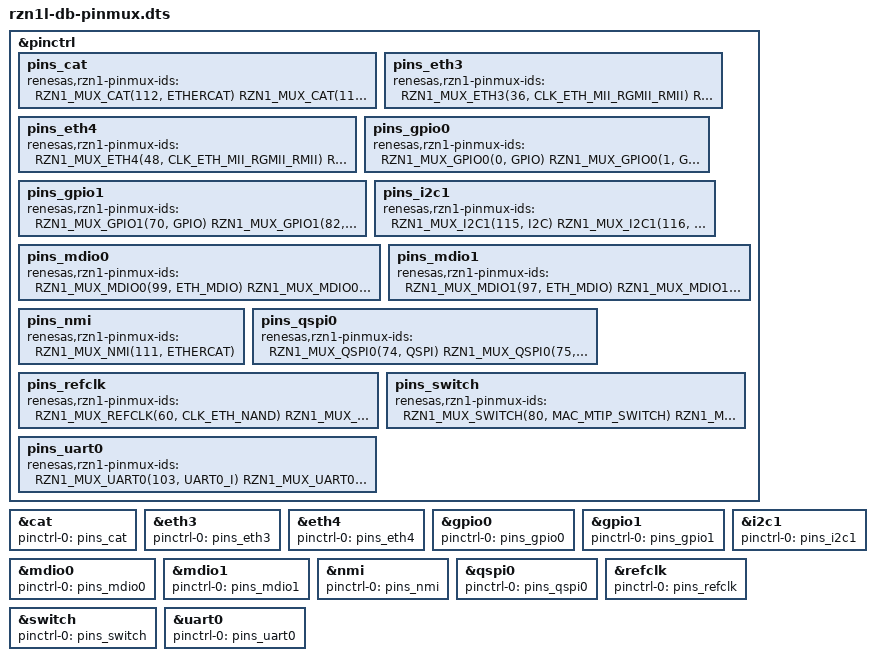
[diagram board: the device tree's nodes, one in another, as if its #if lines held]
/*
 * This file was autogenerated
 * DO NOT EDIT
 * (C) 2015-2016 Renesas Electronics Europe, LTD
 * All rights reserved.
 *
 * Redistribution and use in source and binary forms, with or without
 * modification, are permitted provided that the following conditions are met:
 *
 * 1. Redistributions of source code must retain the above copyright notice,
 * this list of conditions and the following disclaimer.
 *
 * 2. Redistributions in binary form must reproduce the above copyright notice,
 * this list of conditions and the following disclaimer in the documentation
 * and/or other materials provided with the distribution.
 *
 * THIS SOFTWARE IS PROVIDED BY THE COPYRIGHT HOLDERS AND CONTRIBUTORS "AS IS"
 * AND ANY EXPRESS OR IMPLIED WARRANTIES, INCLUDING, BUT NOT LIMITED TO, THE
 * IMPLIED WARRANTIES OF MERCHANTABILITY AND FITNESS FOR A PARTICULAR PURPOSE
 * ARE DISCLAIMED. IN NO EVENT SHALL THE COPYRIGHT HOLDER OR CONTRIBUTORS BE
 * LIABLE FOR ANY DIRECT, INDIRECT, INCIDENTAL, SPECIAL, EXEMPLARY, OR
 * CONSEQUENTIAL DAMAGES (INCLUDING, BUT NOT LIMITED TO, PROCUREMENT OF
 * SUBSTITUTE GOODS OR SERVICES; LOSS OF USE, DATA, OR PROFITS; OR BUSINESS
 * INTERRUPTION) HOWEVER CAUSED AND ON ANY THEORY OF LIABILITY, WHETHER IN
 * CONTRACT, STRICT LIABILITY, OR TORT (INCLUDING NEGLIGENCE OR OTHERWISE)
 * ARISING IN ANY WAY OUT OF THE USE OF THIS SOFTWARE, EVEN IF ADVISED OF THE
 * POSSIBILITY OF SUCH DAMAGE.
 */

#include "rzn1.dtsi"

/*
 * AUTOGENERATED DO NOT EDIT
 *
 * Renesas RZ/N1L-DB board
 * This file only sets the pin function by default.
 *
 * You can override the default mux pullup/down and drive by
 * defining the following macros in the board file before
 * including this.
 */

#ifndef RZN1_MUX_DEFAULT
#define RZN1_MUX_DEFAULT RZN1_MUX
#endif

#ifndef RZN1_MUX_CAT
#define RZN1_MUX_CAT RZN1_MUX_DEFAULT
#endif
#ifndef RZN1_MUX_ETH3
#define RZN1_MUX_ETH3 RZN1_MUX_PNONE_6MA
#endif
#ifndef RZN1_MUX_ETH4
#define RZN1_MUX_ETH4 RZN1_MUX_PNONE_6MA
#endif
#ifndef RZN1_MUX_GPIO
#define RZN1_MUX_GPIO RZN1_MUX_DEFAULT
#endif
#ifndef RZN1_MUX_GPIO0
#define RZN1_MUX_GPIO0 RZN1_MUX_GPIO
#endif
#ifndef RZN1_MUX_GPIO1
#define RZN1_MUX_GPIO1 RZN1_MUX_GPIO
#endif
#ifndef RZN1_MUX_I2C1
#define RZN1_MUX_I2C1 RZN1_MUX_12MA
#endif
#ifndef RZN1_MUX_MDIO
#define RZN1_MUX_MDIO RZN1_MUX_DEFAULT
#endif
#ifndef RZN1_MUX_MDIO0
#define RZN1_MUX_MDIO0 RZN1_MUX_MDIO
#endif
#ifndef RZN1_MUX_MDIO1
#define RZN1_MUX_MDIO1 RZN1_MUX_MDIO
#endif
#ifndef RZN1_MUX_NMI
#define RZN1_MUX_NMI RZN1_MUX_DEFAULT
#endif
#ifndef RZN1_MUX_QSPI0
#define RZN1_MUX_QSPI0 RZN1_MUX_PNONE
#endif
#ifndef RZN1_MUX_REFCLK
#define RZN1_MUX_REFCLK RZN1_MUX_PNONE
#endif
#ifndef RZN1_MUX_SWITCH
#define RZN1_MUX_SWITCH RZN1_MUX_DEFAULT
#endif
#ifndef RZN1_MUX_UART
#define RZN1_MUX_UART RZN1_MUX_DEFAULT
#endif
#ifndef RZN1_MUX_UART0
#define RZN1_MUX_UART0 RZN1_MUX_UART
#endif

&pinctrl {
	pins_cat: pins_cat {
		renesas,rzn1-pinmux-ids = <
			RZN1_MUX_CAT(112, ETHERCAT)	/* CAT_I2CDATA */
			RZN1_MUX_CAT(113, ETHERCAT)	/* CAT_I2CCLK */
		>;
	};
	pins_eth3: pins_eth3 {
		renesas,rzn1-pinmux-ids = <
			RZN1_MUX_ETH3(36, CLK_ETH_MII_RGMII_RMII)	/* ETH3_TXCLK */
			RZN1_MUX_ETH3(37, CLK_ETH_MII_RGMII_RMII)	/* ETH3_TXD[0] */
			RZN1_MUX_ETH3(38, CLK_ETH_MII_RGMII_RMII)	/* ETH3_TXD[1] */
			RZN1_MUX_ETH3(39, CLK_ETH_MII_RGMII_RMII)	/* ETH3_TXD[2] */
			RZN1_MUX_ETH3(40, CLK_ETH_MII_RGMII_RMII)	/* ETH3_TXD[3] */
			RZN1_MUX_ETH3(41, CLK_ETH_MII_RGMII_RMII)	/* ETH3_TXEN */
			RZN1_MUX_ETH3(42, CLK_ETH_MII_RGMII_RMII)	/* ETH3_RXCLK */
			RZN1_MUX_ETH3(43, CLK_ETH_MII_RGMII_RMII)	/* ETH3_RXD[0] */
			RZN1_MUX_ETH3(44, CLK_ETH_MII_RGMII_RMII)	/* ETH3_RXD[1] */
			RZN1_MUX_ETH3(45, CLK_ETH_MII_RGMII_RMII)	/* ETH3_RXD[2] */
			RZN1_MUX_ETH3(46, CLK_ETH_MII_RGMII_RMII)	/* ETH3_RXD[3] */
			RZN1_MUX_ETH3(47, CLK_ETH_MII_RGMII_RMII)	/* ETH3_RXDV */
			RZN1_MUX_ETH3(67, CLK_ETH_MII_RGMII_RMII)	/* ETH3_RXER */
			RZN1_MUX_ETH3(68, CLK_ETH_MII_RGMII_RMII)	/* ETH3_CRS */
			RZN1_MUX_ETH3(69, CLK_ETH_MII_RGMII_RMII)	/* ETH3_COL */
		>;
	};
	pins_eth4: pins_eth4 {
		renesas,rzn1-pinmux-ids = <
			RZN1_MUX_ETH4(48, CLK_ETH_MII_RGMII_RMII)	/* ETH4_TXCLK */
			RZN1_MUX_ETH4(49, CLK_ETH_MII_RGMII_RMII)	/* ETH4_TXD[0] */
			RZN1_MUX_ETH4(50, CLK_ETH_MII_RGMII_RMII)	/* ETH4_TXD[1] */
			RZN1_MUX_ETH4(51, CLK_ETH_MII_RGMII_RMII)	/* ETH4_TXD[2] */
			RZN1_MUX_ETH4(52, CLK_ETH_MII_RGMII_RMII)	/* ETH4_TXD[3] */
			RZN1_MUX_ETH4(53, CLK_ETH_MII_RGMII_RMII)	/* ETH4_TXEN */
			RZN1_MUX_ETH4(54, CLK_ETH_MII_RGMII_RMII)	/* ETH4_RXCLK */
			RZN1_MUX_ETH4(55, CLK_ETH_MII_RGMII_RMII)	/* ETH4_RXD[0] */
			RZN1_MUX_ETH4(56, CLK_ETH_MII_RGMII_RMII)	/* ETH4_RXD[1] */
			RZN1_MUX_ETH4(57, CLK_ETH_MII_RGMII_RMII)	/* ETH4_RXD[2] */
			RZN1_MUX_ETH4(58, CLK_ETH_MII_RGMII_RMII)	/* ETH4_RXD[3] */
			RZN1_MUX_ETH4(59, CLK_ETH_MII_RGMII_RMII)	/* ETH4_RXDV */
			RZN1_MUX_ETH4(71, CLK_ETH_MII_RGMII_RMII)	/* ETH4_RXER */
			RZN1_MUX_ETH4(72, CLK_ETH_MII_RGMII_RMII)	/* ETH4_CRS */
			RZN1_MUX_ETH4(73, CLK_ETH_MII_RGMII_RMII)	/* ETH4_COL */
		>;
	};
	pins_gpio0: pins_gpio0 {
		renesas,rzn1-pinmux-ids = <
			RZN1_MUX_GPIO0(0, GPIO)		/* GPIO0A[0] */
			RZN1_MUX_GPIO0(1, GPIO)		/* GPIO0B[0] */
			RZN1_MUX_GPIO0(2, GPIO)		/* GPIO0B[1] */
			RZN1_MUX_GPIO0(3, GPIO)		/* GPIO0A[1] */
			RZN1_MUX_GPIO0(4, GPIO)		/* GPIO0A[2] */
			RZN1_MUX_GPIO0(5, GPIO)		/* GPIO0B[2] */
			RZN1_MUX_GPIO0(6, GPIO)		/* GPIO0B[3] */
			RZN1_MUX_GPIO0(7, GPIO)		/* GPIO0B[4] */
			RZN1_MUX_GPIO0(8, GPIO)		/* GPIO0B[5] */
			RZN1_MUX_GPIO0(9, GPIO)		/* GPIO0A[3] */
			RZN1_MUX_GPIO0(10, GPIO)	/* GPIO0A[4] */
			RZN1_MUX_GPIO0(11, GPIO)	/* GPIO0B[6] */
			RZN1_MUX_GPIO0(62, GPIO)	/* GPIO0A[25] */
			RZN1_MUX_GPIO0(63, GPIO)	/* GPIO0A[26] */
			RZN1_MUX_GPIO0(64, GPIO)	/* GPIO0A[27] */
			RZN1_MUX_GPIO0(65, GPIO)	/* GPIO0A[28] */
			RZN1_MUX_GPIO0(66, GPIO)	/* Eth 0 reset (GPIO0A[29]) */
		>;
	};
	pins_gpio1: pins_gpio1 {
		renesas,rzn1-pinmux-ids = <
			RZN1_MUX_GPIO1(70, GPIO)	/* Eth 0 IRQ (GPIO1A[1]) */
			RZN1_MUX_GPIO1(82, GPIO)	/* GPIO1B[13] */
			RZN1_MUX_GPIO1(83, GPIO)	/* GPIO1B[14] */
			RZN1_MUX_GPIO1(84, GPIO)	/* GPIO1B[15] */
			RZN1_MUX_GPIO1(85, GPIO)	/* GPIO1B[16] */
			RZN1_MUX_GPIO1(86, GPIO)	/* GPIO1B[17] */
			RZN1_MUX_GPIO1(87, GPIO)	/* GPIO1B[18] */
			RZN1_MUX_GPIO1(88, GPIO)	/* GPIO1B[19] */
			RZN1_MUX_GPIO1(89, GPIO)	/* GPIO1B[20] */
			RZN1_MUX_GPIO1(90, GPIO)	/* GPIO1B[21] */
			RZN1_MUX_GPIO1(91, GPIO)	/* GPIO1B[22] */
			RZN1_MUX_GPIO1(92, GPIO)	/* GPIO1B[23] */
			RZN1_MUX_GPIO1(93, GPIO)	/* GPIO1B[24] */
			RZN1_MUX_GPIO1(94, GPIO)	/* Eth 3 and 4 reset (GPIO1B[25]) */
			RZN1_MUX_GPIO1(95, GPIO)	/* Eth 3 IRQ (GPIO1A[5]) */
			RZN1_MUX_GPIO1(96, GPIO)	/* Eth 4 IRQ (GPIO1A[6]) */
			RZN1_MUX_GPIO1(105, GPIO)	/* GPIO1A[15] */
			RZN1_MUX_GPIO1(106, GPIO)	/* GPIO1A[16] */
			RZN1_MUX_GPIO1(107, GPIO)	/* GPIO1A[17] */
			RZN1_MUX_GPIO1(108, GPIO)	/* GPIO1A[18] */
			RZN1_MUX_GPIO1(114, GPIO)	/* GPIO1A[24] */
			RZN1_MUX_GPIO1(117, GPIO)	/* GPIO1A[27] */
			RZN1_MUX_GPIO1(118, GPIO)	/* GPIO1A[28] */
		>;
	};
	pins_i2c1: pins_i2c1 {
		renesas,rzn1-pinmux-ids = <
			RZN1_MUX_I2C1(115, I2C)		/* I2C1_SCL */
			RZN1_MUX_I2C1(116, I2C)		/* I2C1_SDA */
		>;
	};
	pins_mdio0: pins_mdio0 {
		renesas,rzn1-pinmux-ids = <
			RZN1_MUX_MDIO0(99, ETH_MDIO)	/* MDIO0_MDC */
			RZN1_MUX_MDIO0(100, ETH_MDIO)	/* MDIO0_MDIO */
			RZN1_MUX_MDIO0(170, MDIO_MUX_MAC0)	/* MDIO0_MUX_MAC0 */
		>;
	};
	pins_mdio1: pins_mdio1 {
		renesas,rzn1-pinmux-ids = <
			RZN1_MUX_MDIO1(97, ETH_MDIO)	/* MDIO1_MDC */
			RZN1_MUX_MDIO1(98, ETH_MDIO)	/* MDIO1_MDIO */
			RZN1_MUX_MDIO1(171, MDIO_MUX_SWITCH)	/* MDIO1_MUX_SWITCH */
		>;
	};
	pins_nmi: pins_nmi {
		renesas,rzn1-pinmux-ids = <
			RZN1_MUX_NMI(111, ETHERCAT)	/* NMI_CORTEXM[3] */
		>;
	};
	pins_qspi0: pins_qspi0 {
		renesas,rzn1-pinmux-ids = <
			RZN1_MUX_QSPI0(74, QSPI)	/* QSPI0_CS_N[0] */
			RZN1_MUX_QSPI0(75, QSPI)	/* QSPI0_IO[3] */
			RZN1_MUX_QSPI0(76, QSPI)	/* QSPI0_IO[2] */
			RZN1_MUX_QSPI0(77, QSPI)	/* QSPI0_IO[1] */
			RZN1_MUX_QSPI0(78, QSPI)	/* QSPI0_IO[0] */
			RZN1_MUX_QSPI0(79, QSPI)	/* QSPI0_CLK */
		>;
	};
	pins_refclk: pins_refclk {
		renesas,rzn1-pinmux-ids = <
			RZN1_MUX_REFCLK(60, CLK_ETH_NAND)	/* REFCLK_MII[0] */
			RZN1_MUX_REFCLK(61, CLK_ETH_NAND)	/* REFCLK_MII[1] */
		>;
	};
	pins_switch: pins_switch {
		renesas,rzn1-pinmux-ids = <
			RZN1_MUX_SWITCH(80, MAC_MTIP_SWITCH)	/* SWITCH_MII_LINK[5] */
			RZN1_MUX_SWITCH(81, MAC_MTIP_SWITCH)	/* SWITCH_MII_LINK[4] */
		>;
	};
	pins_uart0: pins_uart0 {
		renesas,rzn1-pinmux-ids = <
			RZN1_MUX_UART0(103, UART0_I)	/* UART0_TXD */
			RZN1_MUX_UART0(104, UART0_I)	/* UART0_RXD */
		>;
	};
};

&cat {
	pinctrl-names = "default";
	pinctrl-0 = <&pins_cat>;
};
&eth3 {
	pinctrl-names = "default";
	pinctrl-0 = <&pins_eth3>;
};
&eth4 {
	pinctrl-names = "default";
	pinctrl-0 = <&pins_eth4>;
};
&gpio0 {
	pinctrl-names = "default";
	pinctrl-0 = <&pins_gpio0>;
};
&gpio1 {
	pinctrl-names = "default";
	pinctrl-0 = <&pins_gpio1>;
};
&i2c1 {
	pinctrl-names = "default";
	pinctrl-0 = <&pins_i2c1>;
};
&mdio0 {
	pinctrl-names = "default";
	pinctrl-0 = <&pins_mdio0>;
};
&mdio1 {
	pinctrl-names = "default";
	pinctrl-0 = <&pins_mdio1>;
};
&nmi {
	pinctrl-names = "default";
	pinctrl-0 = <&pins_nmi>;
};
&qspi0 {
	pinctrl-names = "default";
	pinctrl-0 = <&pins_qspi0>;
};
&refclk {
	pinctrl-names = "default";
	pinctrl-0 = <&pins_refclk>;
};
&switch {
	pinctrl-names = "default";
	pinctrl-0 = <&pins_switch>;
};
&uart0 {
	pinctrl-names = "default";
	pinctrl-0 = <&pins_uart0>;
};

/*
 * This is the compressed Renesas Pinmux Web App data structure; this is
 * used to allow uploading this file back into the web app, make some
 * more changes and generate/save the DTS again. It is not used by Linux
 * in any way.
 */
#ifdef JSON_PRESET
N4IgdghgtgpiBcIBKMwwM4XQAiQLQHoA5ARgBkBaAEQCFsAjAewgCcATEAGhAAcIBjANYQA5nEQAbEgE4AbF14wWASx4ALJRAnoE
AbRABhAIIAVBQFETACRIXrAFjtWArAoDiABQCSAeVvdPXwAmd28fAGYFLyCDEO4AWSpffxBE4IUieK8FAEUAZW8UpHMAMQMyAGkF
PIB1LxMDKwUAVSMkE1sAXW4RHmVGAH1IWB14UCDpBBBzABc1bAAGbBYMGBmFWVdEWfmlryQcjcntuexw7H3D7gB2Bamd7HsLg4US
INsT+fOIMDZH5dW624b3kiESBmwHisAE0SNhAj5XkFrlM0j5ITC4QiQABfHp9RijXT2a6yEiyTgksnXSmkkgADlpZOkTKCC1ZJFZ
QVZ4VZ9lZzlZFKpyM412c9ne3PFkpIvJl735CpIguVFOVNOVjOVLIVbLFEqC7wNkqNJqN8sNQSVVtVVvVVs1Vu1Vt1hvC7IV4U5X
ul7stkvCNsDguczmu9Pp/LDEfpgqpEaZ1xZVPp7NTnNTfsl9gD1uD1vjpPpDpzTpzLpzLLD9JV0ectbDnBrKopLfDzYbKsZ7erJA
W1ub/aCRdk0kZVOkKeut3TM4Wmfn3JJt15K4W/PXRduwvnNPXE/n0+u/dpJ8XJ+54Vk9nsLOv9mc7Ifzk5L6vzJp15kjPCcYWvJ/
k+m4zsaK5muBa6gSB46LuOV7OGOgrhIhcicChY77jOHrNgsY7SKGeFTru1zhFBpHRuSQRts47wkJ0OJAA===
#endif
